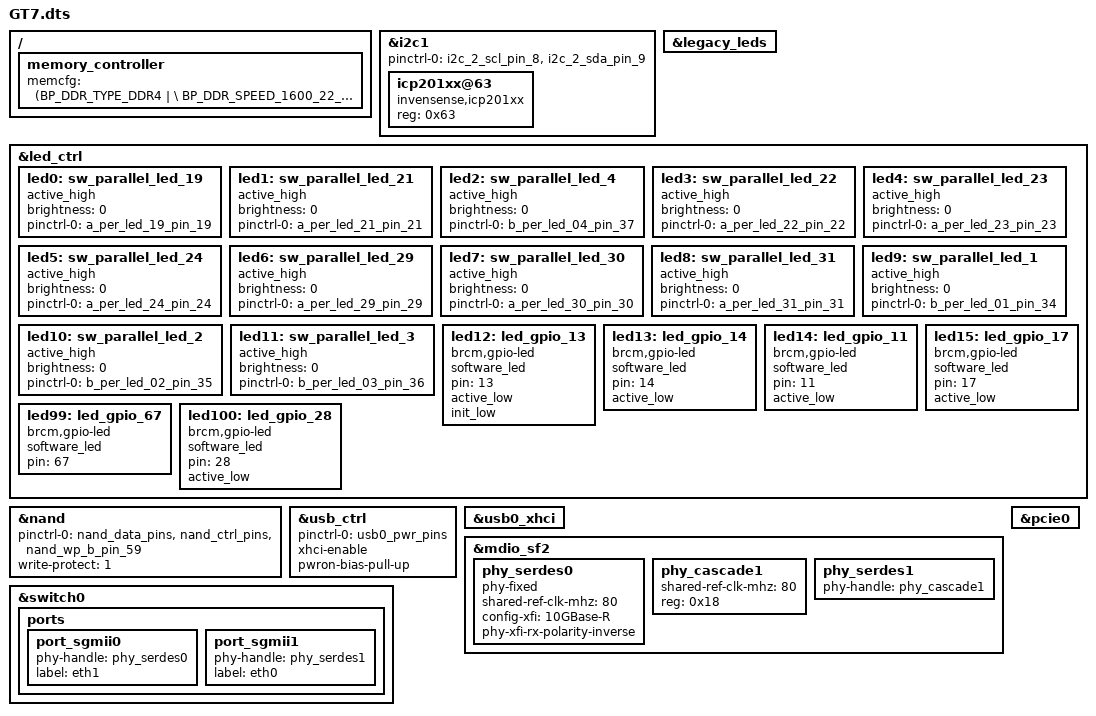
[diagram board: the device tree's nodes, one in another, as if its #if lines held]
#include "6766.dtsi"

/ {
    memory_controller {
        memcfg = <(BP_DDR_TYPE_DDR4       | \
            BP_DDR_SPEED_1600_22_22_22    | \
            BP_DDR_TOTAL_SIZE_2048MB      | \
            BP_DDR_DEVICE_WIDTH_16        | \
            BP_DDR_TOTAL_WIDTH_16BIT      | \
            BP_DDR_6766_DEFAULT           | \
            BP_DDR_CONFIG_DEBUG)>;
    };

/* remove mark if need
	buttons {
		compatible = "brcm,buttons";

		reset_button {
			ext_irq = <&bca_extintr 18 GPIO_ACTIVE_LOW (BCA_EXTINTR_TYPE_LOW_LEVEL | BCA_EXTINTR_TYPE_SENSE_EDGE)>;
			press {
				print = "Button Press -- Hold for 5s to do restore to default";
			};
			hold {
				rst_to_dflt = <5>;
			};
			release {
				reset = <0>;
			};
		};

		ses_button {
			ext_irq = <&bca_extintr 6 GPIO_ACTIVE_LOW (BCA_EXTINTR_TYPE_LOW_LEVEL | BCA_EXTINTR_TYPE_SENSE_EDGE)>;
			release {
				ses_short_period = <0>;
				ses_long_period = <3>;
			};
		};
	};
*/
};

// For ICP-20100 pressure sensor
&i2c1 {
	pinctrl-names = "default";
	pinctrl-0 = <&i2c_2_scl_pin_8 &i2c_2_sda_pin_9>;
	status = "okay";
	icp201xx@63{
		compatible = "invensense,icp201xx";
		reg = <0x63>;
	};
};

&legacy_leds {
};

&led_ctrl {
    pinctrl-names = "default";

    /* LED_RED */
    led0: sw_parallel_led_19 {
        active_high;
        brightness = <0>;
        pinctrl-0 = <&a_per_led_19_pin_19>;
        status = "okay";
    };
    /* LED_GREEN */
    led1: sw_parallel_led_21 {
        active_high;
        brightness = <0>;
        pinctrl-0 = <&a_per_led_21_pin_21>;
        status = "okay";
    };
    /* LED_BLUE */
    led2: sw_parallel_led_4 {
        active_high;
        brightness = <0>;
        pinctrl-0 = <&b_per_led_04_pin_37>;
        status = "okay";
    };

    /* LED_RED_A */
    led3: sw_parallel_led_22 {
        active_high;
        brightness = <0>;
        pinctrl-0 = <&a_per_led_22_pin_22>;
        status = "okay";
    };
    /* LED_BLUE_A */
    led4: sw_parallel_led_23 {
        active_high;
        brightness = <0>;
        pinctrl-0 = <&a_per_led_23_pin_23>;
        status = "okay";
    };
    /* LED_GREEN_A */
    led5: sw_parallel_led_24 {
        active_high;
        brightness = <0>;
        pinctrl-0 = <&a_per_led_24_pin_24>;
        status = "okay";
    };

    /* LED_RED_B */
    led6: sw_parallel_led_29 {
        active_high;
        brightness = <0>;
        pinctrl-0 = <&a_per_led_29_pin_29>;
        status = "okay";
    };
    /* LED_BLUE_B */
    led7: sw_parallel_led_30 {
        active_high;
        brightness = <0>;
        pinctrl-0 = <&a_per_led_30_pin_30>;
        status = "okay";
    };
    /* LED_GREEN_B */
    led8: sw_parallel_led_31 {
        active_high;
        brightness = <0>;
        pinctrl-0 = <&a_per_led_31_pin_31>;
        status = "okay";
    };

    /* LED_RED_C */
    led9: sw_parallel_led_1 {
        active_high;
        brightness = <0>;
        pinctrl-0 = <&b_per_led_01_pin_34>;
        status = "okay";
    };
    /* LED_BLUE_C */
    led10: sw_parallel_led_2 {
        active_high;
        brightness = <0>;
        pinctrl-0 = <&b_per_led_02_pin_35>;
        status = "okay";
    };
    /* LED_GREEN_C */
    led11: sw_parallel_led_3 {
        active_high;
        brightness = <0>;
        pinctrl-0 = <&b_per_led_03_pin_36>;
        status = "okay";
    };

    /* Power_LED: GPIO LED */
    led12: led_gpio_13 {
        compatible = "brcm,gpio-led";
        software_led;
        pin = <13>;
        active_low;
        init_low;
    };
    /* WAN_LED */
    led13: led_gpio_14 {
        compatible = "brcm,gpio-led";
        software_led;
        pin = <14>;
        active_low;
    };
    /* WAN_RED_LED */
    led14: led_gpio_11 {
        compatible = "brcm,gpio-led";
        software_led;
        pin = <11>;
        active_low;
    };
    /* WLAN_LED */
    led15: led_gpio_17 {
        compatible = "brcm,gpio-led";
        software_led;
        pin = <17>;
        active_low;
    };

	/* USB Power */
	led99:led_gpio_67 {
		compatible = "brcm,gpio-led";
		software_led;
		pin = <67>;
	};
	/* MxL86282C reset */
	led100: led_gpio_28 {
		compatible = "brcm,gpio-led";
		software_led;
		pin = <28>;
		active_low;
	};
};

&nand {
    pinctrl-0 = <&nand_data_pins &nand_ctrl_pins &nand_wp_b_pin_59>;
    write-protect = <1>;
    status = "okay";
};

&usb_ctrl {
    pinctrl-names="default";
    pinctrl-0 = <&usb0_pwr_pins>;
    status = "okay";
    xhci-enable;
    pwron-bias-pull-up;
};

&usb0_xhci {
    status = "okay";
};

&mdio_sf2 {
    /* Port PHY mapping:
            port_imp -8#0- port_gphy <----> phy_gphy
                      # 5- port_sgmii0 <--> phy_serdes0 -- MxL86252C USXGMII1
                      #                                    |-- BCM84991
                      # 6- port_sgmii1 <--> phy_serdes1 -  phy_cascade1 -- BCM84991
     */
	/* Remove, since it's not installed in the hardware.
    phy_gphy {
        status = "okay";
    };
	*/

    /* Enable SerDes0 for MxL86252C USXGMII1 */
    phy_serdes0 {
        phy-fixed;
        shared-ref-clk-mhz = <80>;
        config-xfi = "10GBase-R";
        phy-xfi-rx-polarity-inverse;
        status = "okay";
    };
    
    phy_cascade1 {
        shared-ref-clk-mhz = <80>;
        reg = <0x18>;
        status = "okay";
    };
    phy_serdes1 {
        phy-handle = <&phy_cascade1>;
        status = "okay";
    };
};

&switch0 {

    ports {
        /* Remove, since it's not installed in the hardware.
		port_gphy {
            phy-handle = <&phy_gphy>;
            status = "okay";
        };
		*/

        port_sgmii0 {
            phy-handle = <&phy_serdes0>;
            status = "okay";
            label = "eth1";
        };

        port_sgmii1 {
            phy-handle = <&phy_serdes1>;
            status = "okay";
            label = "eth0";
        };
    };
};

#if defined(CONFIG_BCM_PCIE_HCD) || defined(CONFIG_BCM_PCIE_HCD_MODULE)
/**********************************************************************/
/* GPIO: Add one define per GPIO (individual or shared) regulator     */
/*       - Skip if no GPIO regulators in use                          */
/**********************************************************************/
#define PCIE0_REG_GPIO    15    /* PCIE0_PWR_CTRL for vreg_pcie0 node */

#include "../bcm_wlan_regulator.dtsi"

/**********************************************************************/
/* Shared: Add brcm,supply-names = "vreg-pcieX" for shared PCIe nodes */
/*         - Skip if not using shared GPIO regulators                 */
/**********************************************************************/

/**********************************************************************/
/* PCIe: Add status = "okay" for each PCIe slots of this boiard       */
/*       - Skip if this is a derivative board (already done in base)  */
/**********************************************************************/
&pcie0 {
    status = "okay";
};
#endif //#if defined(CONFIG_BCM_PCIE_HCD) || defined(CONFIG_BCM_PCIE_HCD_MODULE)
